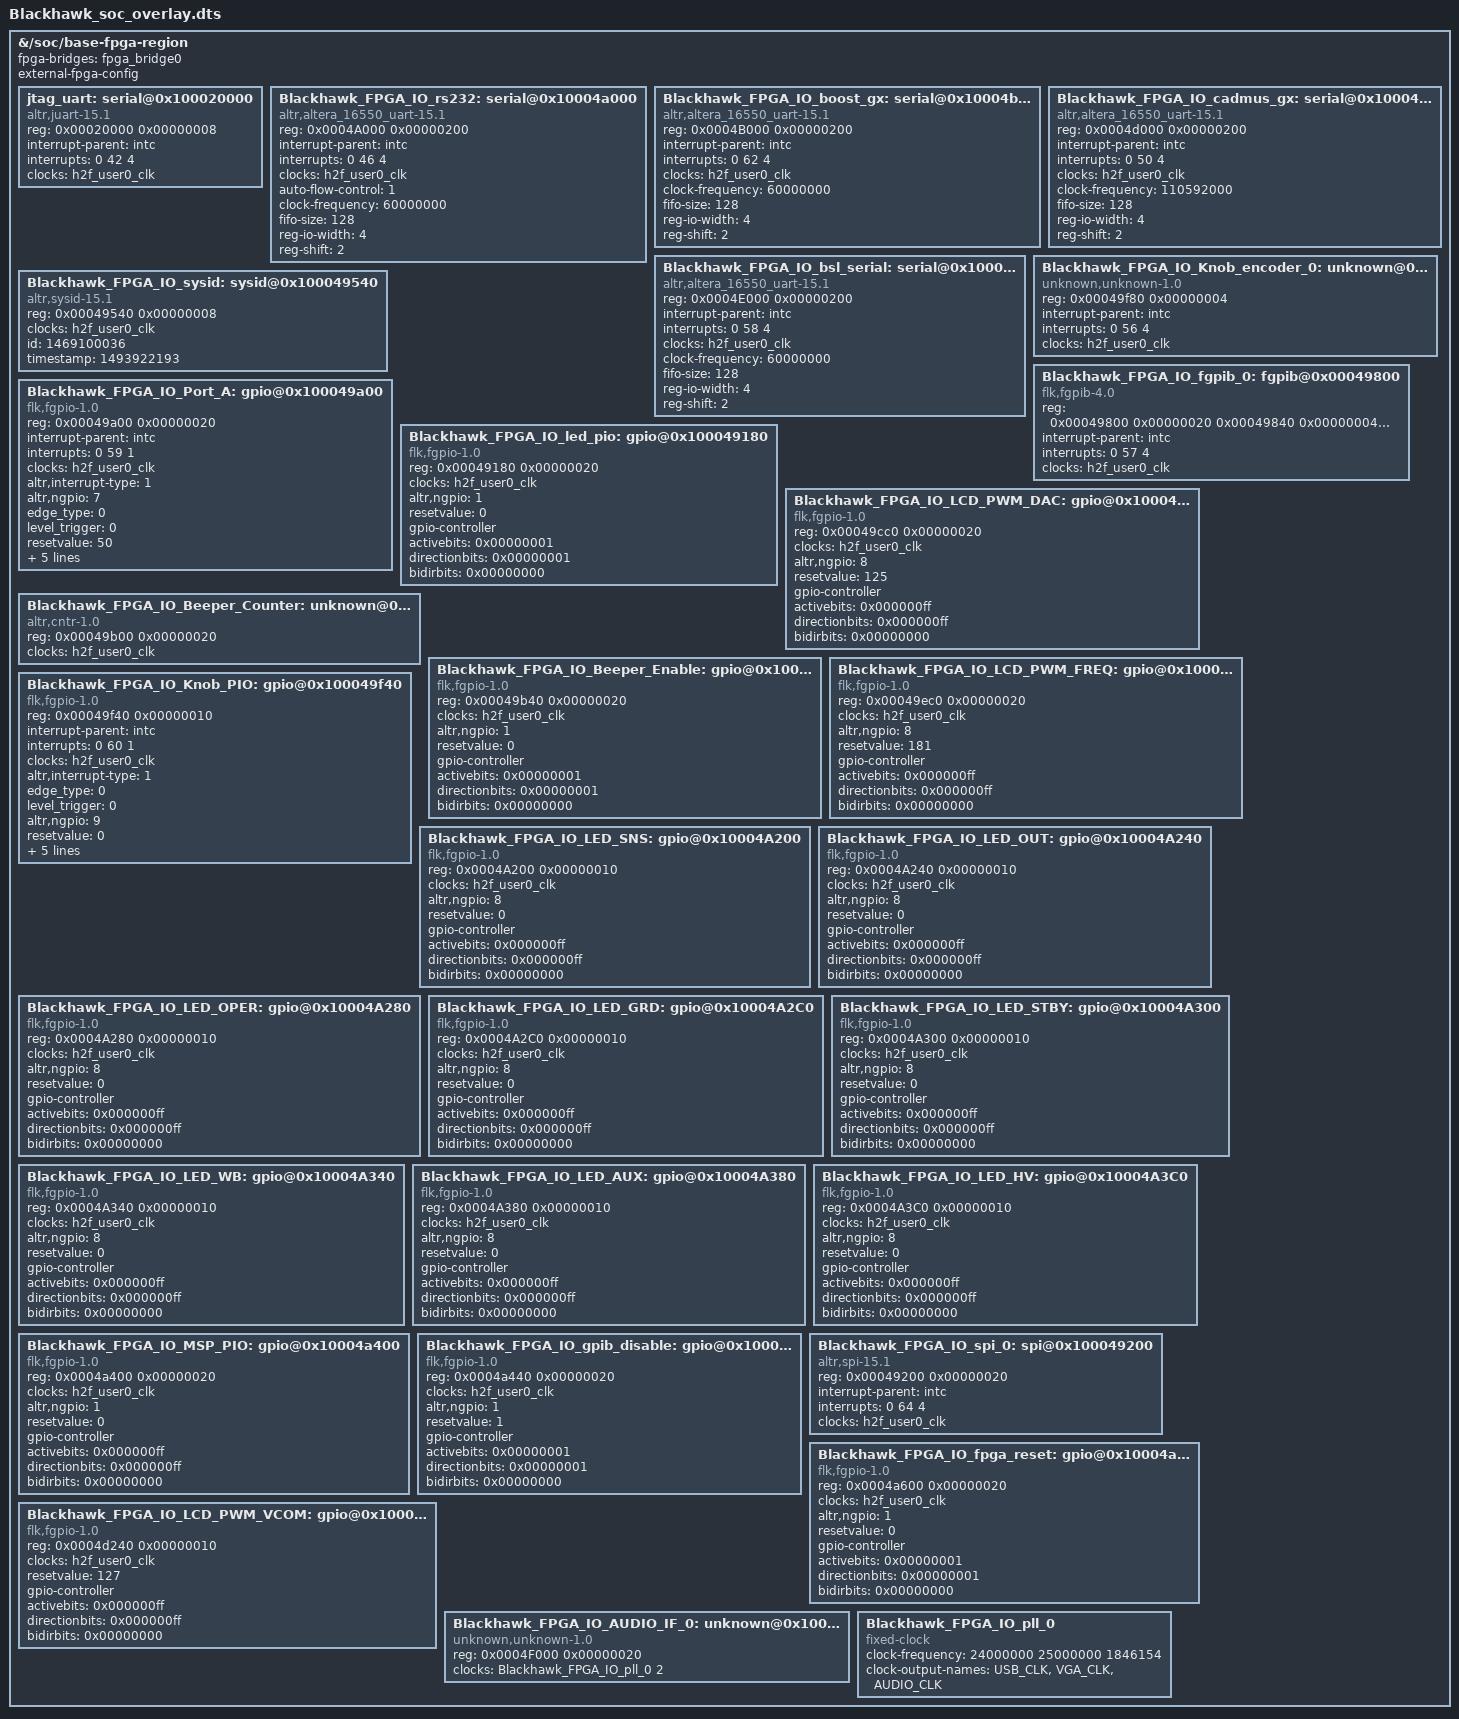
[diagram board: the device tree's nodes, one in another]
/*
 * This devicetree is generated by sopc2dts version 15.1 [94267f754b718da09506aebbe5343be8fdba1582] on Thu May 04 12:59:35 PDT 2017
 * Sopc2dts is written by Walter Goossens <waltergoossens@home.nl>
 * in cooperation with the nios2 community <nios2-dev@lists.rocketboards.org>
 */
 /dts-v1/;
 /plugin/;

/{
    fragment@0 {
        target-path = "/soc/base-fpga-region";
        #address-cells = <1>;
        #size-cells = <1>;

        __overlay__ {
            #address-cells = <1>;
            #size-cells = <1>;
            ranges = <0 0xff200000 0x00200000>;
            fpga-bridges = <&fpga_bridge0>;

            external-fpga-config;

            jtag_uart: serial@0x100020000 {
                compatible = "altr,juart-15.1", "altr,juart-1.0";
                reg = < 0x00020000 0x00000008 >;
                interrupt-parent = < &intc >;
                interrupts = < 0 42 4 >;
                clocks = < &h2f_user0_clk >;
            };

            Blackhawk_FPGA_IO_rs232: serial@0x10004a000 {
                compatible = "altr,altera_16550_uart-15.1", "altr,16550-FIFO128", "ns16550a";
                reg = < 0x0004A000 0x00000200 >;
                interrupt-parent = < &intc >;
                interrupts = < 0 46 4 >;
                clocks = < &h2f_user0_clk >;
                auto-flow-control = < 1 >;	/* embeddedsw.dts.params.auto-flow-control type NUMBER */
                clock-frequency = < 60000000 >;	/* embeddedsw.dts.params.clock-frequency type NUMBER */
                fifo-size = < 128 >;	/* embeddedsw.dts.params.fifo-size type NUMBER */
                reg-io-width = < 4 >;	/* embeddedsw.dts.params.reg-io-width type NUMBER */
                reg-shift = < 2 >;	/* embeddedsw.dts.params.reg-shift type NUMBER */
            }; //end serial@0x10004A000 (Lancer_FPGA_IO_rs232)

            Blackhawk_FPGA_IO_boost_gx: serial@0x10004b000 {
                compatible = "altr,altera_16550_uart-15.1", "altr,16550-FIFO128", "ns16550a";
                reg = < 0x0004B000 0x00000200 >;
                interrupt-parent = < &intc >;
                interrupts = < 0 62 4 >;
                clocks = < &h2f_user0_clk >;
                clock-frequency = < 60000000 >;	/* embeddedsw.dts.params.clock-frequency type NUMBER */
                fifo-size = < 128 >;	/* embeddedsw.dts.params.fifo-size type NUMBER */
                reg-io-width = < 4 >;	/* embeddedsw.dts.params.reg-io-width type NUMBER */
                reg-shift = < 2 >;	/* embeddedsw.dts.params.reg-shift type NUMBER */
            };

            Blackhawk_FPGA_IO_cadmus_gx: serial@0x10004d000 {
                compatible = "altr,altera_16550_uart-15.1", "altr,16550-FIFO128", "ns16550a";
                reg = < 0x0004d000 0x00000200 >;
                interrupt-parent = < &intc >;
                interrupts = < 0 50 4 >;
                clocks = < &h2f_user0_clk >;
                clock-frequency = < 110592000 >; /* embeddedsw.dts.params.clock-frequency type NUMBER */
                fifo-size = < 128 >;	/* embeddedsw.dts.params.fifo-size type NUMBER */
                reg-io-width = < 4 >;	/* embeddedsw.dts.params.reg-io-width type NUMBER */
                reg-shift = < 2 >;	/* embeddedsw.dts.params.reg-shift type NUMBER */
            }; //end serial@0x10004d000 (Blackhawk_FPGA_IO_cadmus_gx)

            Blackhawk_FPGA_IO_bsl_serial: serial@0x10004e000 {
                compatible = "altr,altera_16550_uart-15.1", "altr,16550-FIFO128", "ns16550a";
                reg = < 0x0004E000 0x00000200 >;
                interrupt-parent = < &intc >;
                interrupts = < 0 58 4 >;
                clocks = < &h2f_user0_clk >;
                clock-frequency = < 60000000 >;	/* embeddedsw.dts.params.clock-frequency type NUMBER */
                fifo-size = < 128 >;	/* embeddedsw.dts.params.fifo-size type NUMBER */
                reg-io-width = < 4 >;	/* embeddedsw.dts.params.reg-io-width type NUMBER */
                reg-shift = < 2 >;	/* embeddedsw.dts.params.reg-shift type NUMBER */
            }; //end serial@0x10004E000 (Lancer_FPGA_IO_bsl_serial)

            Blackhawk_FPGA_IO_Knob_encoder_0: unknown@0x100049f80 {
                compatible = "unknown,unknown-1.0";
                reg = < 0x00049f80 0x00000004 >;
                interrupt-parent = < &intc >;
                interrupts = < 0 56 4 >;
                clocks = < &h2f_user0_clk >;
            }; //end unknown@0x100049f80 (Blackhawk_FPGA_IO_Knob_encoder_0)

            Blackhawk_FPGA_IO_sysid: sysid@0x100049540 {
                compatible = "altr,sysid-15.1", "altr,sysid-1.0";
                reg = < 0x00049540 0x00000008 >;
                clocks = < &h2f_user0_clk >;
                id = < 1469100036 >;	/* embeddedsw.dts.params.id type NUMBER */
                timestamp = < 1493922193 >;	/* embeddedsw.dts.params.timestamp type NUMBER */
            }; //end sysid@0x100049540 (Blackhawk_FPGA_IO_sysid)

            /* commented until we switch GPIB drivers */
            /*
            Blackhawk_FPGA_IO_fmh_gpib_0: gpib@0x100049800 {
                compatible = "fmhess,fmh_gpib_core";
                reg = < 0x00049800 0x00000080 >,
                    < 0x00049880 0x00000008 >;
                reg-names = "gpib_control_status", "dma_fifos";
                interrupt-parent = < &intc >;
                interrupts = < 0 57 4 >;
                clocks = < &h2f_user0_clk >;
                dma-names = "rxtx";
                dmas = < &pdma 0 >;
            };
            */

            Blackhawk_FPGA_IO_fgpib_0: fgpib@0x00049800 {
                compatible = "flk,fgpib-4.0";
                reg = < 0x00049800 0x00000020 
                    0x00049840 0x00000004 
                    0x00049880 0x00000004 >;
                reg-names = "s0", "s1", "s2";
                interrupt-parent = < &intc >;
                interrupts = < 0 57 4 >;
                clocks = < &h2f_user0_clk >;
            };

            Blackhawk_FPGA_IO_Port_A: gpio@0x100049a00 {
                compatible = "flk,fgpio-1.0";
                /* compatible = "altr,pio-17.0", "altr,pio-1.0"; */
                reg = < 0x00049a00 0x00000020 >;
                interrupt-parent = < &intc >;
                interrupts = < 0 59 1 >;
                clocks = < &h2f_user0_clk >;
                altr,interrupt-type = < 1 >;
                altr,ngpio = <7>;
                edge_type = < 0 >;
                level_trigger = < 0 >;
                resetvalue = < 50 >;
                #gpio-cells = < 2 >;
                gpio-controller;
                activebits = < 0x0000007f >;
                directionbits = < 0x00000001 >;
                bidirbits = < 0x00000000 >;
                flk,interrupt_type = < 1 >;
            };

            Blackhawk_FPGA_IO_led_pio: gpio@0x100049180 {
                compatible = "flk,fgpio-1.0";
                /* compatible = "altr,pio-17.0", "altr,pio-1.0"; */
                reg = < 0x00049180 0x00000020 >;
                clocks = < &h2f_user0_clk >;
                altr,ngpio = <1>;
                resetvalue = < 0 >;	/* embeddedsw.dts.params.resetvalue type NUMBER */
                #gpio-cells = < 2 >;
                gpio-controller;
                activebits = < 0x00000001 >;	/* appended from boardinfo */
                directionbits = < 0x00000001 >;	/* appended from boardinfo */
                bidirbits = < 0x00000000 >;	/* appended from boardinfo */
            }; //end gpio@0x100049180 (Blackhawk_FPGA_IO_led_pio)

            Blackhawk_FPGA_IO_LCD_PWM_DAC: gpio@0x100049cc0 {
                compatible = "flk,fgpio-1.0";	/* appended from boardinfo */
                /* compatible = "altr,pio-17.0", "altr,pio-1.0"; */
                reg = < 0x00049cc0 0x00000020 >;
                clocks = < &h2f_user0_clk >;
                altr,ngpio = <8>;
                resetvalue = < 125 >;	/* embeddedsw.dts.params.resetvalue type NUMBER */
                #gpio-cells = < 2 >;
                gpio-controller;
                activebits = < 0x000000ff >;	/* appended from boardinfo */
                directionbits = < 0x000000ff >;	/* appended from boardinfo */
                bidirbits = < 0x00000000 >;	/* appended from boardinfo */
            }; //end gpio@0x100049cc0 (Blackhawk_FPGA_IO_LCD_PWM_DAC)

            Blackhawk_FPGA_IO_Beeper_Counter: unknown@0x100049b00 {
                compatible = "altr,cntr-1.0";	/* appended from boardinfo */
                reg = < 0x00049b00 0x00000020 >;
                clocks = < &h2f_user0_clk >;
            }; //end unknown@0x100049b00 (Blackhawk_FPGA_IO_Beeper_Counter)

            Blackhawk_FPGA_IO_Beeper_Enable: gpio@0x100049b40 {
                compatible = "flk,fgpio-1.0";	/* appended from boardinfo */
                /* compatible = "altr,pio-17.0", "altr,pio-1.0"; */
                reg = < 0x00049b40 0x00000020 >;
                clocks = < &h2f_user0_clk >;
                altr,ngpio = <1>;
                resetvalue = < 0 >;	/* embeddedsw.dts.params.resetvalue type NUMBER */
                #gpio-cells = < 2 >;
                gpio-controller;
                activebits = < 0x00000001 >;	/* appended from boardinfo */
                directionbits = < 0x00000001 >;	/* appended from boardinfo */
                bidirbits = < 0x00000000 >;	/* appended from boardinfo */
            }; //end gpio@0x100049b40 (Blackhawk_FPGA_IO_Beeper_Enable)

            Blackhawk_FPGA_IO_LCD_PWM_FREQ: gpio@0x100049ec0 {
                compatible = "flk,fgpio-1.0";	/* appended from boardinfo */
                /* compatible = "altr,pio-17.0", "altr,pio-1.0"; */
                reg = < 0x00049ec0 0x00000020 >;
                clocks = < &h2f_user0_clk >;
                altr,ngpio = <8>;
                resetvalue = < 181 >;	/* embeddedsw.dts.params.resetvalue type NUMBER */
                #gpio-cells = < 2 >;
                gpio-controller;
                activebits = < 0x000000ff >;	/* appended from boardinfo */
                directionbits = < 0x000000ff >;	/* appended from boardinfo */
                bidirbits = <0x00000000>;	/* appended from boardinfo */
            }; //end gpio@0x100049ec0 (Blackhawk_FPGA_IO_LCD_PWM_FREQ)

            Blackhawk_FPGA_IO_Knob_PIO: gpio@0x100049f40 {
                compatible = "flk,fgpio-1.0";	/* appended from boardinfo */
                /* compatible = "altr,pio-17.0", "altr,pio-1.0"; */
                reg = < 0x00049f40 0x00000010 >;
                interrupt-parent = < &intc >;
                interrupts = < 0 60 1 >;
                clocks = <&h2f_user0_clk>;
                altr,interrupt-type = < 1 >;	/* embeddedsw.dts.params.altr,interrupt-type type NUMBER */
                edge_type = < 0 >;	/* embeddedsw.dts.params.edge_type type NUMBER */
                level_trigger = < 0 >;	/* embeddedsw.dts.params.level_trigger type NUMBER */
                altr,ngpio = <9>;
                resetvalue = < 0 >;	/* embeddedsw.dts.params.resetvalue type NUMBER */
                #gpio-cells = < 2 >;
                gpio-controller;
                activebits = < 0x000001ff >;	/* appended from boardinfo */
                directionbits = < 0x000001ff >;	/* appended from boardinfo */
                bidirbits = < 0x00000000 >;	/* appended from boardinfo */
                flk,interrupt_type = < 1 >;	/* appended from boardinfo */
            }; //end gpio@0x100049f40 (Blackhawk_FPGA_IO_Knob_PIO)

            Blackhawk_FPGA_IO_LED_SNS: gpio@0x10004A200 {
                compatible = "flk,fgpio-1.0";	/* appended from boardinfo */
                reg = < 0x0004A200 0x00000010 >;
                clocks = < &h2f_user0_clk >;
                altr,ngpio = <8>;
                resetvalue = < 0 >;	/* embeddedsw.dts.params.resetvalue type NUMBER */
                #gpio-cells = < 2 >;
                gpio-controller;
                activebits = < 0x000000ff >;	/* appended from boardinfo */
                directionbits = < 0x000000ff >;	/* appended from boardinfo */
                bidirbits = < 0x00000000 >;	/* appended from boardinfo */
            }; //end gpio@0x10004A200 (Lancer_FPGA_IO_LED_SNS)

            Blackhawk_FPGA_IO_LED_OUT: gpio@0x10004A240 {
                compatible = "flk,fgpio-1.0";	/* appended from boardinfo */
                reg = < 0x0004A240 0x00000010 >;
                clocks = < &h2f_user0_clk >;
                altr,ngpio = < 8 >;	/* embeddedsw.dts.params.altr,gpio-bank-width type NUMBER */
                resetvalue = < 0 >;	/* embeddedsw.dts.params.resetvalue type NUMBER */
                #gpio-cells = < 2 >;
                gpio-controller;
                activebits = < 0x000000ff >;	/* appended from boardinfo */
                directionbits = < 0x000000ff >;	/* appended from boardinfo */
                bidirbits = < 0x00000000 >;	/* appended from boardinfo */
            }; //end gpio@0x10004A240 (Lancer_FPGA_IO_LED_OUT)

            Blackhawk_FPGA_IO_LED_OPER: gpio@0x10004A280 {
                compatible = "flk,fgpio-1.0";	/* appended from boardinfo */
                reg = < 0x0004A280 0x00000010 >;
                clocks = < &h2f_user0_clk >;
                altr,ngpio = < 8 >;	/* embeddedsw.dts.params.altr,gpio-bank-width type NUMBER */
                resetvalue = < 0 >;	/* embeddedsw.dts.params.resetvalue type NUMBER */
                #gpio-cells = < 2 >;
                gpio-controller;
                activebits = < 0x000000ff >;	/* appended from boardinfo */
                directionbits = < 0x000000ff >;	/* appended from boardinfo */
                bidirbits = < 0x00000000 >;	/* appended from boardinfo */
            }; //end gpio@0x10004A280 (Lancer_FPGA_IO_LED_OPER)

            Blackhawk_FPGA_IO_LED_GRD: gpio@0x10004A2C0 {
                compatible = "flk,fgpio-1.0";	/* appended from boardinfo */
                reg = < 0x0004A2C0 0x00000010 >;
                clocks = < &h2f_user0_clk >;
                altr,ngpio = < 8 >;	/* embeddedsw.dts.params.altr,gpio-bank-width type NUMBER */
                resetvalue = < 0 >;	/* embeddedsw.dts.params.resetvalue type NUMBER */
                #gpio-cells = < 2 >;
                gpio-controller;
                activebits = < 0x000000ff >;	/* appended from boardinfo */
                directionbits = < 0x000000ff >;	/* appended from boardinfo */
                bidirbits = < 0x00000000 >;	/* appended from boardinfo */
            }; //end gpio@0x10004A2C0 (Lancer_FPGA_IO_LED_GRD)

            Blackhawk_FPGA_IO_LED_STBY: gpio@0x10004A300 {
                compatible = "flk,fgpio-1.0";	/* appended from boardinfo */
                reg = < 0x0004A300 0x00000010 >;
                clocks = < &h2f_user0_clk >;
                altr,ngpio = < 8 >;	/* embeddedsw.dts.params.altr,gpio-bank-width type NUMBER */
                resetvalue = < 0 >;	/* embeddedsw.dts.params.resetvalue type NUMBER */
                #gpio-cells = < 2 >;
                gpio-controller;
                activebits = < 0x000000ff >;	/* appended from boardinfo */
                directionbits = < 0x000000ff >;	/* appended from boardinfo */
                bidirbits = < 0x00000000 >;	/* appended from boardinfo */
            }; //end gpio@0x10004A300 (Lancer_FPGA_IO_LED_STBY)

            Blackhawk_FPGA_IO_LED_WB: gpio@0x10004A340 {
                compatible = "flk,fgpio-1.0";	/* appended from boardinfo */
                reg = < 0x0004A340 0x00000010 >;
                clocks = < &h2f_user0_clk >;
                altr,ngpio = < 8 >;	/* embeddedsw.dts.params.altr,gpio-bank-width type NUMBER */
                resetvalue = < 0 >;	/* embeddedsw.dts.params.resetvalue type NUMBER */
                #gpio-cells = < 2 >;
                gpio-controller;
                activebits = < 0x000000ff >;	/* appended from boardinfo */
                directionbits = < 0x000000ff >;	/* appended from boardinfo */
                bidirbits = < 0x00000000 >;	/* appended from boardinfo */
            }; //end gpio@0x10004A340 (Lancer_FPGA_IO_LED_WB)

            Blackhawk_FPGA_IO_LED_AUX: gpio@0x10004A380 {
                compatible = "flk,fgpio-1.0";	/* appended from boardinfo */
                reg = < 0x0004A380 0x00000010 >;
                clocks = < &h2f_user0_clk >;
                altr,ngpio = < 8 >;	/* embeddedsw.dts.params.altr,gpio-bank-width type NUMBER */
                resetvalue = < 0 >;	/* embeddedsw.dts.params.resetvalue type NUMBER */
                #gpio-cells = < 2 >;
                gpio-controller;
                activebits = < 0x000000ff >;	/* appended from boardinfo */
                directionbits = < 0x000000ff >;	/* appended from boardinfo */
                bidirbits = < 0x00000000 >;	/* appended from boardinfo */
            }; //end gpio@0x10004A380 (Lancer_FPGA_IO_LED_AUX)

            Blackhawk_FPGA_IO_LED_HV: gpio@0x10004A3C0 {
                compatible = "flk,fgpio-1.0";	/* appended from boardinfo */
                reg = < 0x0004A3C0 0x00000010 >;
                clocks = < &h2f_user0_clk >;
                altr,ngpio = < 8 >;	/* embeddedsw.dts.params.altr,gpio-bank-width type NUMBER */
                resetvalue = < 0 >;	/* embeddedsw.dts.params.resetvalue type NUMBER */
                #gpio-cells = < 2 >;
                gpio-controller;
                activebits = < 0x000000ff >;	/* appended from boardinfo */
                directionbits = < 0x000000ff >;	/* appended from boardinfo */
                bidirbits = < 0x00000000 >;	/* appended from boardinfo */
            }; //end gpio@0x10004A3C0 (Lancer_FPGA_IO_LED_HV)

            Blackhawk_FPGA_IO_MSP_PIO: gpio@0x10004a400 {
                compatible = "flk,fgpio-1.0";	/* appended from boardinfo */
                /* compatible = "altr,pio-17.0", "altr,pio-1.0"; */
                reg = < 0x0004a400 0x00000020 >;
                clocks = < &h2f_user0_clk >;
                altr,ngpio = <1>;
                resetvalue = < 0 >;	/* embeddedsw.dts.params.resetvalue type NUMBER */
                #gpio-cells = < 2 >;
                gpio-controller;
                activebits = < 0x000000ff >;	/* appended from boardinfo */
                directionbits = < 0x000000ff >;	/* appended from boardinfo */
                bidirbits = < 0x00000000 >;	/* appended from boardinfo */
            }; //end gpio@0x10004a400 (Blackhawk_FPGA_IO_MSP_PIO)

            Blackhawk_FPGA_IO_gpib_disable: gpio@0x10004a440 {
                compatible = "flk,fgpio-1.0";	/* appended from boardinfo */
                /* compatible = "altr,pio-17.0", "altr,pio-1.0"; */
                reg = < 0x0004a440 0x00000020 >;
                clocks = < &h2f_user0_clk >;
                altr,ngpio = <1>;
                resetvalue = < 1 >;	/* embeddedsw.dts.params.resetvalue type NUMBER */
                #gpio-cells = < 2 >;
                gpio-controller;
                activebits = < 0x00000001 >;	/* appended from boardinfo */
                directionbits = < 0x00000001 >;	/* appended from boardinfo */
                bidirbits = < 0x00000000 >;	/* appended from boardinfo */
            }; //end gpio@0x10004a440 (Blackhawk_FPGA_IO_gpib_disable)

            Blackhawk_FPGA_IO_spi_0: spi@0x100049200 {
                compatible = "altr,spi-15.1", "altr,spi-1.0";
                reg = < 0x00049200 0x00000020 >;
                interrupt-parent = < &intc >;
                interrupts = < 0 64 4 >;
                clocks = < &h2f_user0_clk >;
            }; //end spi@0x100049200 (Blackhawk_FPGA_IO_spi_0)

            Blackhawk_FPGA_IO_fpga_reset: gpio@0x10004a600 {
                compatible = "flk,fgpio-1.0";	/* appended from boardinfo */
                /* compatible = "altr,pio-17.0", "altr,pio-1.0"; */
                reg = < 0x0004a600 0x00000020 >;
                clocks = < &h2f_user0_clk >;
                altr,ngpio = <1>;
                resetvalue = < 0 >;	/* embeddedsw.dts.params.resetvalue type NUMBER */
                #gpio-cells = < 2 >;
                gpio-controller;
                activebits = < 0x00000001 >;	/* appended from boardinfo */
                directionbits = < 0x00000001 >;	/* appended from boardinfo */
                bidirbits = < 0x00000000 >;	/* appended from boardinfo */
            }; //end gpio@0x10004a600 (Blackhawk_FPGA_IO_fpga_reset)

            Blackhawk_FPGA_IO_LCD_PWM_VCOM: gpio@0x10004d240 {
                compatible = "flk,fgpio-1.0";	/* appended from boardinfo */
                reg = < 0x0004d240 0x00000010 >;
                clocks = < &h2f_user0_clk >;
                resetvalue = < 127 >;	/* embeddedsw.dts.params.resetvalue type NUMBER */
                #gpio-cells = < 2 >;
                gpio-controller;
                activebits = <0x000000ff>;	/* appended from boardinfo */
                directionbits = <0x000000ff>;	/* appended from boardinfo */
                bidirbits = <0x00000000>;	/* appended from boardinfo */
            }; //end gpio@0x10004d240 (Nighthawk_FPGA_IO_LCD_PWM_VCOM)

            Blackhawk_FPGA_IO_AUDIO_IF_0: unknown@0x10004F000 {
                compatible = "unknown,unknown-1.0";
                reg = < 0x0004F000 0x00000020 >;
                clocks = < &Blackhawk_FPGA_IO_pll_0 2 >;
            };

            Blackhawk_FPGA_IO_pll_0: Blackhawk_FPGA_IO_pll_0 {
                compatible = "fixed-clock";
                clock-frequency = < 24000000 25000000 1846154 >;
                clock-output-names = "USB_CLK", "VGA_CLK", "AUDIO_CLK";
            };
        };
    };
}; //end /
